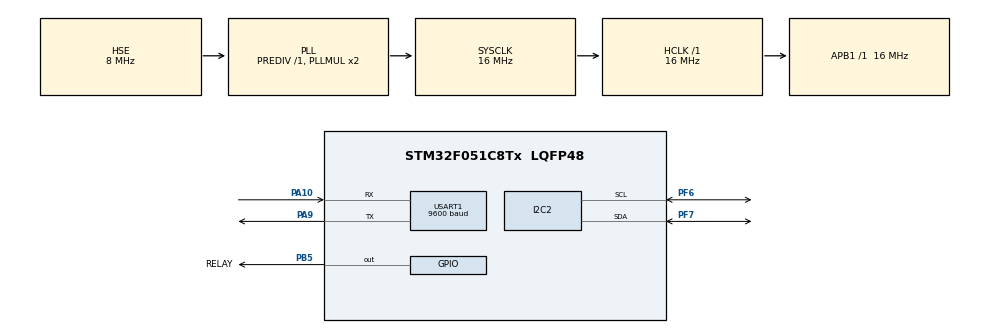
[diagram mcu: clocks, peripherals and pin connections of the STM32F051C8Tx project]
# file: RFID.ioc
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I2C2.Timing=0x00303D5B
Mcu.Family=STM32F0
Mcu.Name=STM32F051C8Tx
Mcu.Package=LQFP48
NVIC.TIM15_IRQn=true\:0\:0\:false\:false\:true\:true\:true
NVIC.USART1_IRQn=true\:0\:0\:false\:false\:true\:true\:true
PA10.Mode=Asynchronous
PA10.Signal=USART1_RX
PA13.Mode=Serial_Wire
PA13.Signal=SYS_SWDIO
PA14.Mode=Serial_Wire
PA14.Signal=SYS_SWCLK
PA9.Mode=Asynchronous
PA9.Signal=USART1_TX
PB5.GPIO_Label=RELAY
PB5.GPIO_ModeDefaultOutputPP=GPIO_MODE_OUTPUT_PP
PB5.GPIO_PuPd=GPIO_NOPULL
PB5.GPIO_Speed=GPIO_SPEED_FREQ_LOW
PB5.PinState=GPIO_PIN_RESET
PB5.Signal=GPIO_Output
PF0-OSC_IN.Mode=HSE-External-Oscillator
PF0-OSC_IN.Signal=RCC_OSC_IN
PF1-OSC_OUT.Mode=HSE-External-Oscillator
PF1-OSC_OUT.Signal=RCC_OSC_OUT
PF6.Mode=I2C
PF6.Signal=I2C2_SCL
PF7.Mode=I2C
PF7.Signal=I2C2_SDA
ProjectManager.HeapSize=0x200
ProjectManager.StackSize=0x400
ProjectManager.TargetToolchain=STM32CubeIDE
RCC.AHBFreq_Value=16000000
RCC.APB1Freq_Value=16000000
RCC.APB1TimFreq_Value=16000000
RCC.HCLKFreq_Value=16000000
RCC.PLLSourceVirtual=RCC_PLLSOURCE_HSE
RCC.RTCClockSelection=RCC_RTCCLKSOURCE_HSE_DIV32
RCC.SYSCLKFreq_VALUE=16000000
RCC.SYSCLKSource=RCC_SYSCLKSOURCE_PLLCLK
TIM15.Period=999
TIM15.Prescaler=15
USART1.BaudRate=9600
USART1.VirtualMode-Asynchronous=VM_ASYNC
VP_TIM15_VS_ClockSourceINT.Mode=Internal
board=custom

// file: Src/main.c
/* USER CODE BEGIN Header */
/**
 ******************************************************************************
 * @file           : main.c
 * @brief          : Main program body
 ******************************************************************************
 * @attention
 *
 * <h2><center>&copy; Copyright (c) 2019 STMicroelectronics.
 * All rights reserved.</center></h2>
 *
 * This software component is licensed by ST under BSD 3-Clause license,
 * the "License"; You may not use this file except in compliance with the
 * License. You may obtain a copy of the License at:
 *                        opensource.org/licenses/BSD-3-Clause
 *
 ******************************************************************************
 */
/* USER CODE END Header */

#include "main.h"

/* USER CODE BEGIN Includes */
#include "RFID.h"

/* USER CODE END Includes */

I2C_HandleTypeDef hi2c2;

TIM_HandleTypeDef htim15;

UART_HandleTypeDef huart1;

/* USER CODE BEGIN PV */
uint8_t   get_rfid;
extern uint8_t  Detect_card;
uint8_t mode = 0xff ;

uint8_t USERnn;

extern uint8_t lock_flag;

uint8_t save_admin_card_for_tst[3][12];
uint8_t load_admin_card_for_tst[3][12];

/* USER CODE END PV */

void SystemClock_Config(void);
static void MX_GPIO_Init(void);
static void MX_I2C2_Init(void);
static void MX_TIM15_Init(void);
static void MX_USART1_UART_Init(void);
/* USER CODE BEGIN PFP */

/**
 * @brief  None
 * @param  None
 * @retval None
 */
void card_Manage(uint8_t mode){

	Detect_card=0;

	if(mode == NewCard){
		if(Card_Authentication(&USERnn) == true ){
			USERnn = New_Card();
			// ADD_log(NewCard_register ,USERnn);
		}
		else {
			//ADD_log(UnSuccessful_login ,0);
		}
	}

	else if(mode == Login){
		if(Card_Authentication(&USERnn) == false ){
			//ADD_log(Successful_login ,USERnn);
		}
		else {
			//ADD_log(UnSuccessful_login ,0);
		}
	}

	else if(mode == DeleteCard){
		if(Delete_Card(&USERnn) == true ){
			//ADD_log(RemoveCard ,USERnn);
		}
		else {
		}
		mode=0;
	}

	else if(mode == DeleteAllCard){
		if(IS_Admin_Card() == true ){
			Delete_AllCard();
			//ADD_log(RemoveAllCard ,0);
		}
		else{

		}
		mode=0;
	}

	else if (mode == New_Admin_Card){
		Set_Admin_Card();
		//ADD_log(Save_Admin_Card ,0);
	}

	mode = Login;
}
/* USER CODE END PFP */

int main(void)
{

  /* MCU Configuration--------------------------------------------------------*/

  /* Reset of all peripherals, Initializes the Flash interface and the Systick. */
  HAL_Init();

  /* Configure the system clock */
  SystemClock_Config();

  /* Initialize all configured peripherals */
  MX_GPIO_Init();
  MX_I2C2_Init();
  MX_TIM15_Init();
  MX_USART1_UART_Init();
  /* USER CODE BEGIN 2 */
	HAL_TIM_Base_Start_IT(&htim15);
	HAL_UART_Receive_IT(&huart1,&get_rfid ,1);

  /* USER CODE END 2 */

  /* Infinite loop */
  /* USER CODE BEGIN WHILE */

	mode = Login;

	HAL_Delay(500);

	while (1)
	{

		 HAL_Delay(100);
		/*********************************RFID MANAGE**************************/
		if(!lock_flag){

			if(mode == Login && Detect_card){
				/* Login */
				Detect_card=0;
				card_Manage(mode);
			}

			if(mode == NewCard && Detect_card){
				/* NewCard */
				Detect_card=0;
				card_Manage(mode);
				mode = Login;
			}

			if(mode == DeleteCard && Detect_card){
				/* DeleteCard */
				Detect_card=0;
				card_Manage(DeleteCard);
				mode = Login;
			}

			if(mode == DeleteAllCard && Detect_card){
				/* DeleteAllCard */
				Detect_card=0;
				card_Manage(DeleteAllCard);
				mode = Login;
			}

		}
    /* USER CODE END WHILE */

	}
}

void SystemClock_Config(void)
{
  RCC_OscInitTypeDef RCC_OscInitStruct = {0};
  RCC_ClkInitTypeDef RCC_ClkInitStruct = {0};
  RCC_PeriphCLKInitTypeDef PeriphClkInit = {0};

  /** Initializes the CPU, AHB and APB busses clocks
  */
  RCC_OscInitStruct.OscillatorType = RCC_OSCILLATORTYPE_HSE;
  RCC_OscInitStruct.HSEState = RCC_HSE_ON;
  RCC_OscInitStruct.PLL.PLLState = RCC_PLL_ON;
  RCC_OscInitStruct.PLL.PLLSource = RCC_PLLSOURCE_HSE;
  RCC_OscInitStruct.PLL.PLLMUL = RCC_PLL_MUL2;
  RCC_OscInitStruct.PLL.PREDIV = RCC_PREDIV_DIV1;
  if (HAL_RCC_OscConfig(&RCC_OscInitStruct) != HAL_OK)
  {
    Error_Handler();
  }
  /** Initializes the CPU, AHB and APB busses clocks
  */
  RCC_ClkInitStruct.ClockType = RCC_CLOCKTYPE_HCLK|RCC_CLOCKTYPE_SYSCLK
                              |RCC_CLOCKTYPE_PCLK1;
  RCC_ClkInitStruct.SYSCLKSource = RCC_SYSCLKSOURCE_PLLCLK;
  RCC_ClkInitStruct.AHBCLKDivider = RCC_SYSCLK_DIV1;
  RCC_ClkInitStruct.APB1CLKDivider = RCC_HCLK_DIV1;

  if (HAL_RCC_ClockConfig(&RCC_ClkInitStruct, FLASH_LATENCY_0) != HAL_OK)
  {
    Error_Handler();
  }
  PeriphClkInit.PeriphClockSelection = RCC_PERIPHCLK_USART1;
  PeriphClkInit.Usart1ClockSelection = RCC_USART1CLKSOURCE_PCLK1;
  if (HAL_RCCEx_PeriphCLKConfig(&PeriphClkInit) != HAL_OK)
  {
    Error_Handler();
  }
}

static void MX_I2C2_Init(void)
{

  hi2c2.Instance = I2C2;
  hi2c2.Init.Timing = 0x2000090E;
  hi2c2.Init.OwnAddress1 = 0;
  hi2c2.Init.AddressingMode = I2C_ADDRESSINGMODE_7BIT;
  hi2c2.Init.DualAddressMode = I2C_DUALADDRESS_DISABLE;
  hi2c2.Init.OwnAddress2 = 0;
  hi2c2.Init.OwnAddress2Masks = I2C_OA2_NOMASK;
  hi2c2.Init.GeneralCallMode = I2C_GENERALCALL_DISABLE;
  hi2c2.Init.NoStretchMode = I2C_NOSTRETCH_DISABLE;
  if (HAL_I2C_Init(&hi2c2) != HAL_OK)
  {
    Error_Handler();
  }
  /** Configure Analogue filter
  */
  if (HAL_I2CEx_ConfigAnalogFilter(&hi2c2, I2C_ANALOGFILTER_ENABLE) != HAL_OK)
  {
    Error_Handler();
  }
  /** Configure Digital filter
  */
  if (HAL_I2CEx_ConfigDigitalFilter(&hi2c2, 0) != HAL_OK)
  {
    Error_Handler();
  }

}

static void MX_TIM15_Init(void)
{

  TIM_ClockConfigTypeDef sClockSourceConfig = {0};
  TIM_MasterConfigTypeDef sMasterConfig = {0};

  htim15.Instance = TIM15;
  htim15.Init.Prescaler = 15;
  htim15.Init.CounterMode = TIM_COUNTERMODE_UP;
  htim15.Init.Period = 999;
  htim15.Init.ClockDivision = TIM_CLOCKDIVISION_DIV1;
  htim15.Init.RepetitionCounter = 0;
  htim15.Init.AutoReloadPreload = TIM_AUTORELOAD_PRELOAD_DISABLE;
  if (HAL_TIM_Base_Init(&htim15) != HAL_OK)
  {
    Error_Handler();
  }
  sClockSourceConfig.ClockSource = TIM_CLOCKSOURCE_INTERNAL;
  if (HAL_TIM_ConfigClockSource(&htim15, &sClockSourceConfig) != HAL_OK)
  {
    Error_Handler();
  }
  sMasterConfig.MasterOutputTrigger = TIM_TRGO_RESET;
  sMasterConfig.MasterSlaveMode = TIM_MASTERSLAVEMODE_DISABLE;
  if (HAL_TIMEx_MasterConfigSynchronization(&htim15, &sMasterConfig) != HAL_OK)
  {
    Error_Handler();
  }

}

static void MX_USART1_UART_Init(void)
{

  huart1.Instance = USART1;
  huart1.Init.BaudRate = 9600;
  huart1.Init.WordLength = UART_WORDLENGTH_8B;
  huart1.Init.StopBits = UART_STOPBITS_1;
  huart1.Init.Parity = UART_PARITY_NONE;
  huart1.Init.Mode = UART_MODE_TX_RX;
  huart1.Init.HwFlowCtl = UART_HWCONTROL_NONE;
  huart1.Init.OverSampling = UART_OVERSAMPLING_16;
  huart1.Init.OneBitSampling = UART_ONE_BIT_SAMPLE_DISABLE;
  huart1.AdvancedInit.AdvFeatureInit = UART_ADVFEATURE_NO_INIT;
  if (HAL_UART_Init(&huart1) != HAL_OK)
  {
    Error_Handler();
  }

}

static void MX_GPIO_Init(void)
{
  GPIO_InitTypeDef GPIO_InitStruct = {0};

  /* GPIO Ports Clock Enable */
  __HAL_RCC_GPIOC_CLK_ENABLE();
  __HAL_RCC_GPIOF_CLK_ENABLE();
  __HAL_RCC_GPIOA_CLK_ENABLE();
  __HAL_RCC_GPIOB_CLK_ENABLE();

  /*Configure GPIO pin Output Level */
  HAL_GPIO_WritePin(GPIOC, GPIO_PIN_13, GPIO_PIN_RESET);

  /*Configure GPIO pin Output Level */
  HAL_GPIO_WritePin(RELAY_GPIO_Port, RELAY_Pin, GPIO_PIN_RESET);

  /*Configure GPIO pin : PC13 */
  GPIO_InitStruct.Pin = GPIO_PIN_13;
  GPIO_InitStruct.Mode = GPIO_MODE_OUTPUT_PP;
  GPIO_InitStruct.Pull = GPIO_NOPULL;
  GPIO_InitStruct.Speed = GPIO_SPEED_FREQ_LOW;
  HAL_GPIO_Init(GPIOC, &GPIO_InitStruct);

  /*Configure GPIO pin : RELAY_Pin */
  GPIO_InitStruct.Pin = RELAY_Pin;
  GPIO_InitStruct.Mode = GPIO_MODE_OUTPUT_PP;
  GPIO_InitStruct.Pull = GPIO_NOPULL;
  GPIO_InitStruct.Speed = GPIO_SPEED_FREQ_LOW;
  HAL_GPIO_Init(RELAY_GPIO_Port, &GPIO_InitStruct);

}

void Error_Handler(void)
{
}

/************************ (C) COPYRIGHT STMicroelectronics *****END OF FILE****/
